# M4G6 register map
File version: 0.1
Registers are 32-bit, read-write, reset 0x0 unless marked. A register's access mark holds for its fields unless they carry their own. Offsets are from the block's base; [hi:lo] are bit positions; {n}, {i} and the like mark numbered series.

## PK — Port K
Base 0x400E0900
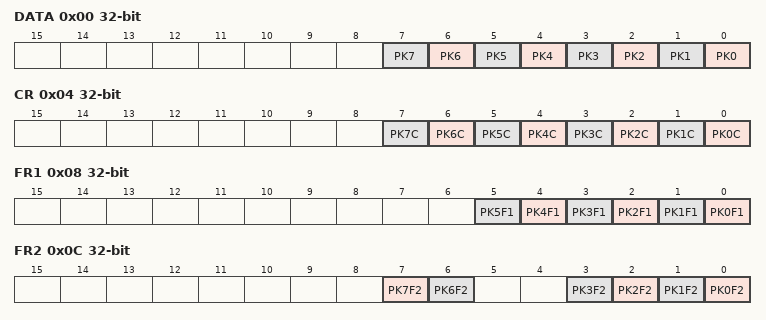
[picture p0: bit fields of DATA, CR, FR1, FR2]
0x00 DATA — Port K Data Register
  [n] PK{n} (n=0..7)
0x04 CR — Port K Output Control Register
  [n] PK{n}C (n=0..7)
0x08 FR1 — Port K Function Register 1
  [n] PK{n}F1 (n=0..5)
0x0C FR2 — Port K Function Register 2
  [7] PK7F2, [6] PK6F2, [n] PK{n}F2 (n=0..3)
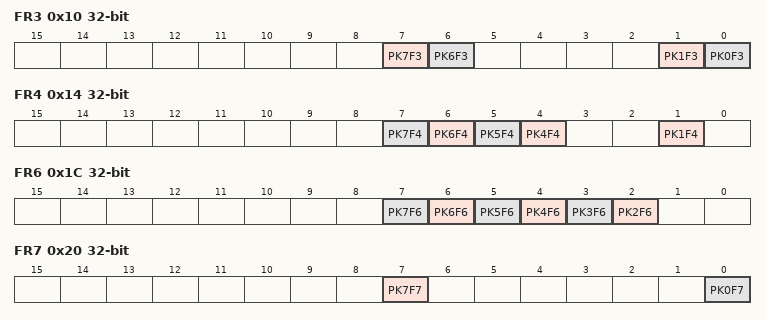
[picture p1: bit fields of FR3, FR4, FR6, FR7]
0x10 FR3 — Port K Function Register 3
  [7] PK7F3, [6] PK6F3, [1] PK1F3, [0] PK0F3
0x14 FR4 — Port K Function Register 4
  [n] PK{n}F4 (n=4..7), [1] PK1F4
0x1C FR6 — Port K Function Register 6
  [n] PK{n}F6 (n=2..7)
0x20 FR7 — Port K Function Register 7
  [7] PK7F7, [0] PK0F7
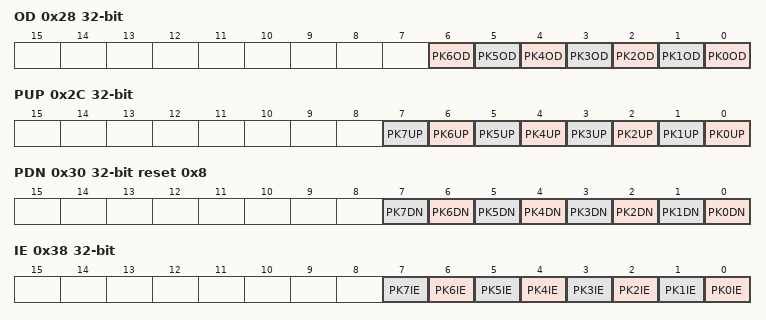
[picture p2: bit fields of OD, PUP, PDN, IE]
0x28 OD — Port K Open Drain Control Register
  [n] PK{n}OD (n=0..6)
0x2C PUP — Port K Pull-up Control Register
  [n] PK{n}UP (n=0..7)
0x30 PDN reset 0x8 — Port K Pull-up Control Register
  [n] PK{n}DN (n=0..7)
0x38 IE — Port K Input Control Register
  [n] PK{n}IE (n=0..7)

## PL — Port L
Base 0x400E0A00
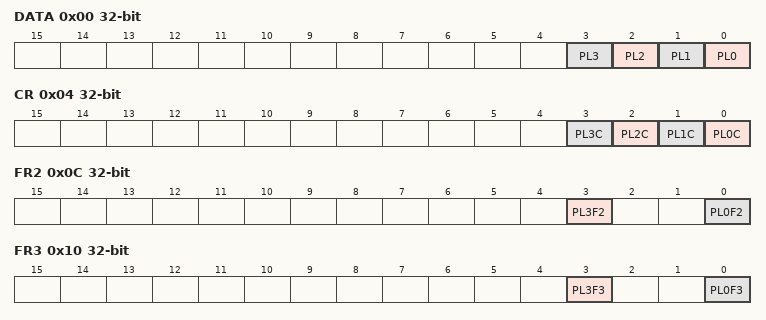
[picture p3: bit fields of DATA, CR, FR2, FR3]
0x00 DATA — Port L Data Register
  [n] PL{n} (n=0..3)
0x04 CR — Port L Output Control Register
  [n] PL{n}C (n=0..3)
0x08 FR1 — Port L Function Register 1
0x0C FR2 — Port L Function Register 2
  [3] PL3F2, [0] PL0F2
0x10 FR3 — Port L Function Register 3
  [3] PL3F3, [0] PL0F3
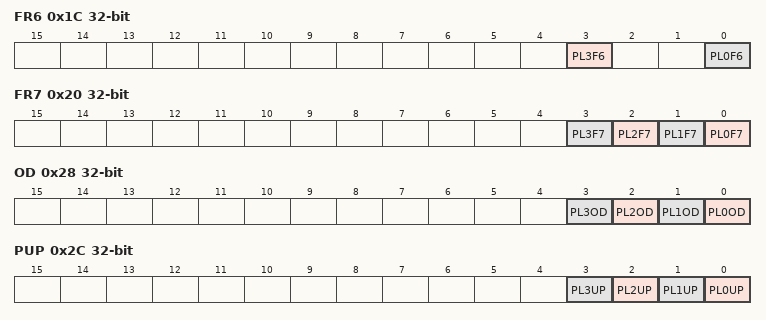
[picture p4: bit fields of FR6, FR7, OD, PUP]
0x1C FR6 — Port L Function Register 6
  [3] PL3F6, [0] PL0F6
0x20 FR7 — Port L Function Register 7
  [n] PL{n}F7 (n=0..3)
0x28 OD — Port L Open Drain Control Register
  [n] PL{n}OD (n=0..3)
0x2C PUP — Port L Pull-up Control Register
  [n] PL{n}UP (n=0..3)
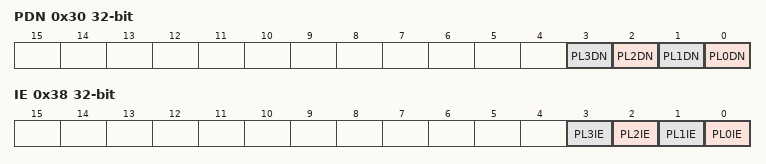
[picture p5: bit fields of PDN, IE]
0x30 PDN — Port L Pull-down Control Register
  [n] PL{n}DN (n=0..3)
0x38 IE — Port L Input Control Register
  [n] PL{n}IE (n=0..3)

## PN — Port N
Base 0x400E0C00
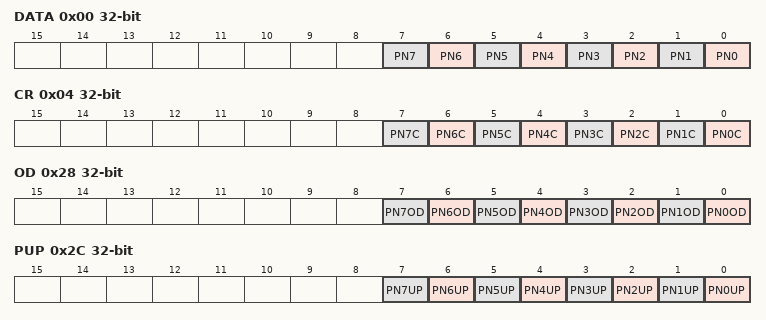
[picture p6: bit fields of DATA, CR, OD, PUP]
0x00 DATA — Port N Data Register
  [n] PN{n} (n=0..7)
0x04 CR — Port N Output Control Register
  [n] PN{n}C (n=0..7)
0x28 OD — Port N Opend Drain Control Register
  [n] PN{n}OD (n=0..7)
0x2C PUP — Port N Pull-up Control Register
  [n] PN{n}UP (n=0..7)
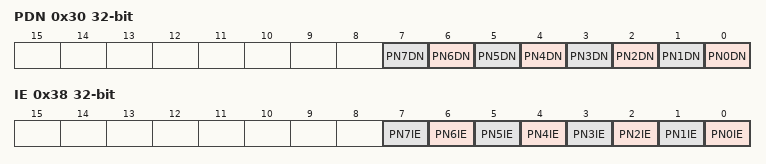
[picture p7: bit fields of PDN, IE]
0x30 PDN — Port N Pull-down Control Register
  [n] PN{n}DN (n=0..7)
0x38 IE — Port N Input Control Register
  [n] PN{n}IE (n=0..7)

## PP — Port P
Base 0x400E0D00
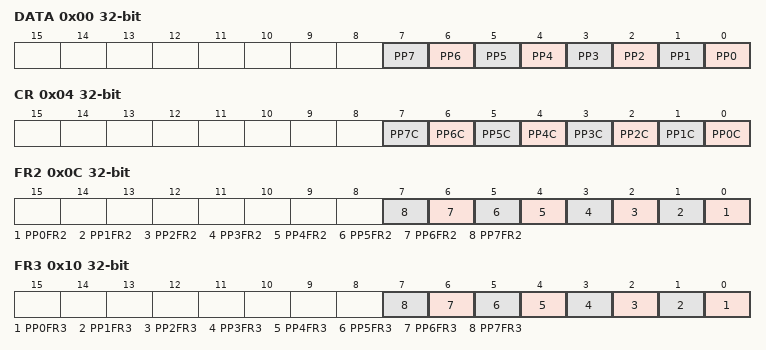
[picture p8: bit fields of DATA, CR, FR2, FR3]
0x00 DATA — Port P Data Register
  [n] PP{n} (n=0..7)
0x04 CR — Port P Output Control Register
  [n] PP{n}C (n=0..7)
0x0C FR2 — Port P Function Register 2
  [n] PP{n}FR2 (n=0..7)
0x10 FR3 — Port P Function Register 3
  [n] PP{n}FR3 (n=0..7)
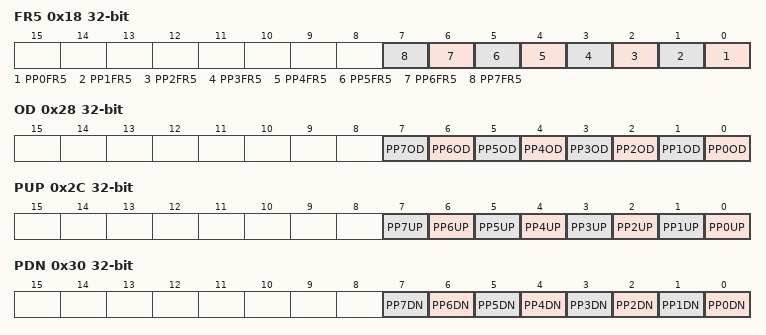
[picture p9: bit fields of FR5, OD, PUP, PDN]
0x18 FR5 — Port P Function Register 5
  [n] PP{n}FR5 (n=0..7)
0x28 OD — Port P Open Drain Control Register
  [n] PP{n}OD (n=0..7)
0x2C PUP — Port P Pull-up Control Register
  [n] PP{n}UP (n=0..7)
0x30 PDN — Port P Pull-down Control Register
  [n] PP{n}DN (n=0..7)
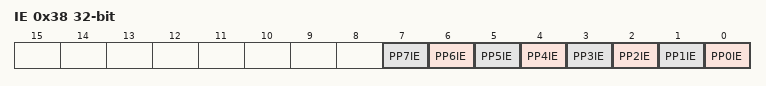
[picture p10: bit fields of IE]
0x38 IE — Port P Input Control Register
  [n] PP{n}IE (n=0..7)

## PT — Port T
Base 0x400E0F00
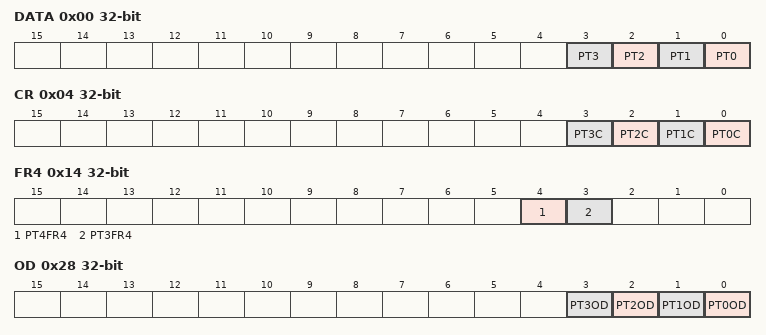
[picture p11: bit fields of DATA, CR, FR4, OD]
0x00 DATA — Port T Data Register
  [n] PT{n} (n=0..3)
0x04 CR — Port T Output Control Register
  [n] PT{n}C (n=0..3)
{0x4+4i} FR{i} (i=1..3) — Port T Function Register {i}
  [3] PT3FR{i}
0x14 FR4 — Port T Function Register 4
  [4] PT4FR4, [3] PT3FR4
0x1C FR6 — Port T Function Register 6
  [3] PT3FR6
0x20 FR7 — Port T Function Register 7
  [2] PT2FR7
0x28 OD — Port T Open Drain Control Register
  [n] PT{n}OD (n=0..3)
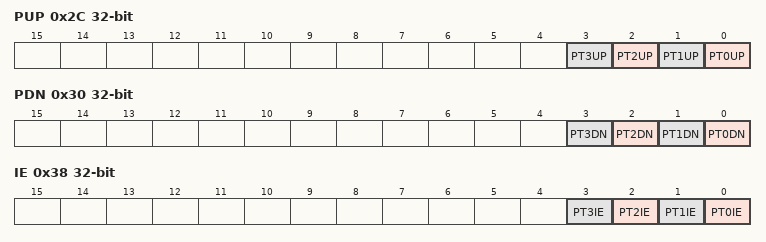
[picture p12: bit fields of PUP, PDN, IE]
0x2C PUP — Port T Pull-up Control Register
  [n] PT{n}UP (n=0..3)
0x30 PDN — Port T Pull-down Control Register
  [n] PT{n}DN (n=0..3)
0x38 IE — Port T Input Control Register
  [n] PT{n}IE (n=0..3)

## PY — Port Y
Base 0x400E1300
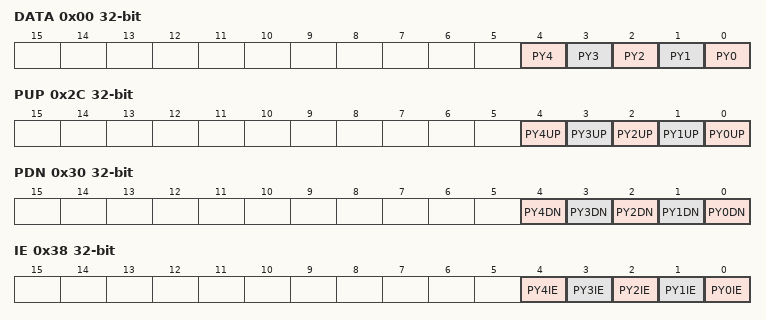
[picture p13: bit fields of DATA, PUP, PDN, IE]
0x00 DATA — Port Y Data Register
  [n] PY{n} (n=0..4)
0x04 CR — Port Y OutPut Control Register
  [4] PY4C
0x08 FR1 — Port Y Function Register 1
  [4] PY4F1
0x14 FR4 — Port Y Function Register 4
  [4] PY4F4
0x28 OD — Port Y Open Drain Control Register
  [4] PY4OD
0x2C PUP — Port Y Pull-up Control Register
  [n] PY{n}UP (n=0..4)
0x30 PDN — Port Y Pull-down Control Register
  [n] PY{n}DN (n=0..4)
0x38 IE — Port Y InPut Control Register
  [n] PY{n}IE (n=0..4)
